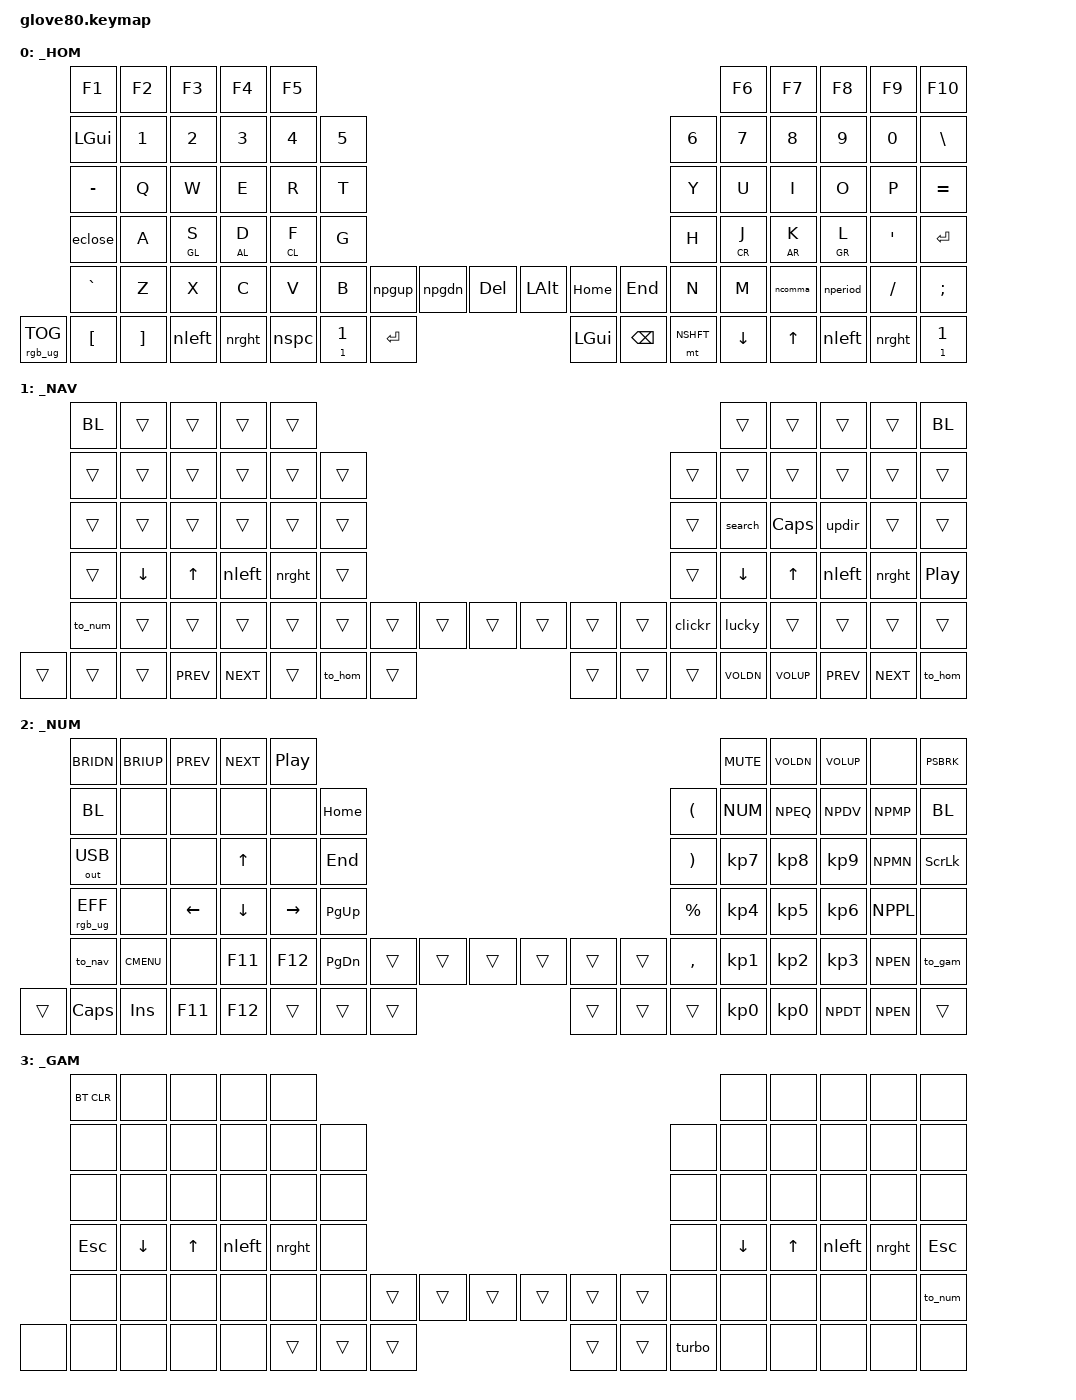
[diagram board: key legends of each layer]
#include <behaviors.dtsi>
#include <dt-bindings/zmk/keys.h>
#include <dt-bindings/zmk/bt.h>
#include <dt-bindings/zmk/ext_power.h>
#include <dt-bindings/zmk/outputs.h>
#include <dt-bindings/zmk/rgb.h>
// mouse import
#include <dt-bindings/zmk/mouse.h>

// helpers
#include "zmk-helpers/helper.h"
// Source desired key-position labels
#include "zmk-helpers/key-labels/glove80.h"

// layers
#define _HOM 0
#define _NAV 1
#define _NUM 2
#define _GAM 3

#define _________ &trans
#define XXXXXXXXX &none

// syntax shortening
#define BRIDN   C_BRI_DN
#define BRIUP   C_BRI_UP
#define PREV    C_PREV
#define NEXT    C_NEXT
#define MUTE    C_MUTE
#define VOLDN   C_VOL_DN
#define VOLUP   C_VOL_UP
#define PSBRK   PAUSE_BREAK
#define NUM     KP_NUM
#define NPEQ    KP_EQUAL
#define NPDV    KP_DIVIDE
#define NPMP    KP_MULTIPLY
#define NPMN    KP_MINUS
#define NPPL    KP_PLUS
#define NPEN    KP_ENTER
#define NPDT    KP_DOT
#define CMENU   K_CMENU
#define CLR     BT_CLR
#define BL bootloader

//left hand mod shortenings
#define CL      LCTRL
#define SL      LSHFT
#define AL      LALT
#define GL      LGUI

//right hand mod shortening
#define CR      RCTRL
#define SR      RSHFT
#define AR      RALT
#define GR      RGUI

// customs
#define NSHFT   RSHIFT TAB
#define NCTRL   LCTRL SP

#define BLU        170
#define GRN         85
#define RED          0
#define PNK        260

#define SAT        100  //saturation
#define BRT         50  //brightness

#define KEYS_L  LC5 LC4 LC3 LC2 LC1 LN5 LN4 LN3 LN2 LN1 LN0 LT5 LT4 LT3 LT2 LT1 LT0 LM5 LM4 LM3 LM2 LM1 LM0 LB5 LB4 LB3 LB2 LB1 LB0 LF5 LF4 LF3 LF2 LF1 // left-hand keys
#define KEYS_R  RC5 RC4 RC3 RC2 RC1 RN5 RN4 RN3 RN2 RN1 RN0 RT5 RT4 RT3 RT2 RT1 RT0 RM5 RM4 RM3 RM2 RM1 RM0 RB5 RB4 RB3 RB2 RB1 RB0 RF5 RF4 RF3 RF2 RF1 // rght-hand keys
#define THUMBS  LH5 LH4 LH3 RH3 RH4 RH5 LH2 LH1 LH0 RH0 RH1 RH2

/* left-hand HRMs */
ZMK_HOLD_TAP(hml,
    flavor = "balanced";
    tapping-term-ms = <280>;
    quick-tap-ms = <200>;                // repeat on tap-into-hold
    require-prior-idle-ms = <150>;
    bindings = <&kp>, <&kp>;
    hold-trigger-key-positions = <KEYS_R THUMBS>;
    hold-trigger-on-release;             // delay positional check until key-release
)
/* right-hand HRMs */
ZMK_HOLD_TAP(hmr,
    flavor = "balanced";
    tapping-term-ms = <280>;
    quick-tap-ms = <200>;                // repeat on tap-into-hold
    require-prior-idle-ms = <150>;
    bindings = <&kp>, <&kp>;
    hold-trigger-key-positions = <KEYS_L THUMBS>;
    hold-trigger-on-release;             // delay positional check until key-release
)


/ {
    macros {
        search: search_highlighted_selection {
            compatible = "zmk,behavior-macro";
            #binding-cells = <0>;
            wait-ms = <30>;
            tap-ms = <30>;
            bindings
                = <&macro_press &kp LCTRL>
                , <&macro_tap &kp C &kp T &kp V>
                , <&macro_release &kp LCTRL>
                , <&macro_tap &kp ENTER>
                ;
        };
        lucky: lucky_search_highlighted_selection {
            compatible = "zmk,behavior-macro";
            #binding-cells = <0>;
            wait-ms = <30>;
            tap-ms = <30>;
            bindings

                // CTRL(C T)
                = <&macro_press &hello_world>
                // , <&macro_tap &kp C &kp T>
                // , <&macro_release &kp LCTRL>

                // // HTTPS
                // , <&macro_tap &kp H &kp T &kp T &kp P &kp S>

                // // :
                // , <&macro_press &kp LSHFT>
                // , <&macro_tap &kp SEMI &kp SEMI>
                // , <&macro_release &kp LSHFT>

                // // //www.google.com/search
                // , <&macro_tap &kp FSLH &kp FSLH &kp W &kp W &kp W &kp DOT &kp G &kp O &kp O &kp G &kp L &kp E &kp DOT &kp C &kp O &kp M &kp FSLH &kp S &kp E &kp A &kp R &kp C>

                // , <&macro_tap &kp H>


                // // ?
                // , <&macro_press &kp LSHFT>
                // , <&macro_tap &kp SEMI>
                // , <&macro_release &kp LSHFT>

                // // copy paste
                // , <&macro_press &kp LCTRL>
                // , <&macro_tap &kp V>
                // , <&macro_release &kp LCTRL>

                // // &
                // , <&macro_press &kp LSHFT>
                // , <&macro_tap &kp N7>
                // , <&macro_release &kp LSHFT>

                // // btnI=I
                // , <&macro_tap &kp B &kp T &kp N &kp I &kp EQUAL &kp I>
                // , <&macro_tap &kp ENTER>
                // // "https://www.google.com/search?q=" SS_LCTL("v") "&btnI=I"
                ;
        };
        cntrc: click_center {
            compatible = "zmk,behavior-macro";
            #binding-cells = <0>;
            bindings
                = <&macro_wait_time 50>
                , <&macro_tap &kp F20 &mkp LCLK>
                ;
        };
        sidec: click_side {
            compatible = "zmk,behavior-macro";
            #binding-cells = <0>;
            bindings
                = <&macro_wait_time 50>
                , <&macro_tap &kp F19 &mkp LCLK>
                ;
        };
        updir: up_directory {
            compatible = "zmk,behavior-macro";
            #binding-cells = <0>;
            wait-ms = <1>;
            tap-ms = <1>;
            bindings
                = <&macro_wait_time 1>
                , <&macro_tap &kp DOT &kp DOT &kp FSLH>
                ;
        };
        to_hom: to_hom {
            compatible = "zmk,behavior-macro";
            wait-ms = <0>;
            tap-ms = <0>;
            #binding-cells = <0>;
            bindings
                = <&macro_press &to _HOM>
                , <&macro_tap &rgb_ug RGB_COLOR_HSB(BLU, SAT, BRT)>
                ;
        };
        to_nav: to_nav {
            compatible = "zmk,behavior-macro";
            wait-ms = <0>;
            tap-ms = <0>;
            #binding-cells = <0>;
            bindings
                = <&macro_press &to _NAV>
                , <&macro_tap &rgb_ug RGB_COLOR_HSB(RED, SAT, BRT)>
                ;
        };
        to_num: to_num {
            compatible = "zmk,behavior-macro";
            wait-ms = <0>;
            tap-ms = <0>;
            #binding-cells = <0>;
            bindings
                = <&macro_press &to _NUM>
                , <&macro_tap &rgb_ug RGB_COLOR_HSB(GRN, SAT, BRT)>
                ;
        };
        to_gam: to_gam {
            compatible = "zmk,behavior-macro";
            wait-ms = <0>;
            tap-ms = <0>;
            #binding-cells = <0>;
            bindings
                = <&macro_press &to _GAM>
                , <&macro_tap &rgb_ug RGB_COLOR_HSB(PNK, SAT, BRT)>
                ;
        };
        htonmo: home_to_nav_momentary {
            compatible = "zmk,behavior-macro";
            wait-ms = <0>;
            tap-ms = <0>;
            #binding-cells = <0>;
            bindings
                = <&macro_tap &rgb_ug RGB_COLOR_HSB(RED, SAT, BRT)>
                , <&macro_press &mo _NAV>
                , <&macro_pause_for_release>
                , <&macro_release &mo _NAV>
                , <&macro_tap &rgb_ug RGB_COLOR_HSB(BLU, SAT, BRT)>
                ;
        };
        turbo: turbo_mouse_click {
            compatible = "zmk,behavior-macro";
            // wait-ms = <5>;
            // tap-ms = <5>;
            #binding-cells = <0>;
            bindings
                = <&macro_tap &mkp LCLK &mkp LCLK &mkp LCLK &mkp LCLK>
                ;
        };
    };

    behaviors {
        hello_world: hello_world {
            compatible = "zmk,behavior-send-string";
            #binding-cells = <0>;
            text = "Hello, world!";
        };

        mtly: mod_tap_layer {
            compatible = "zmk,behavior-hold-tap";
            #binding-cells = <2>;
            tapping-term-ms = <200>;
            bindings = <&htonmo>, <&to_nav>;
        };

        //  SHIFT
        //-----------------------------------------------------------------------------------------------------------------------------------
        npgup: npgdn_up {                                   // Shift + PGUP  = SHFT + WIN + Left        (Send Desktop Left)
            compatible = "zmk,behavior-mod-morph";
            #binding-cells = <0>;
            bindings = <&kp PG_UP>, <&kp LS(LG(LEFT))>;
            mods = <(MOD_LSFT|MOD_RSFT)>;
        };
        npgdn: new_page_down {                              // Shift + PGDN  = SHFT + WIN + Right       (Send Desktop Right)
            compatible = "zmk,behavior-mod-morph";
            #binding-cells = <0>;
            bindings = <&kp PG_DN>, <&kp LS(LG(RIGHT))>;
            mods = <(MOD_LSFT|MOD_RSFT)>;
        };
        intleft: left_intermediate {                        // Shift + Left  = WIN  + CTRL + Left       (Move Desktop Left)
            compatible = "zmk,behavior-mod-morph";
            #binding-cells = <0>;
            bindings = <&kp LEFT>, <&kp LC(LG(LEFT))>;
            mods = <(MOD_LSFT|MOD_RSFT)>;
        };
        intright: right_intermediate {                      // Shift + Right = WIN  + CTRL + Rght       (Move Desktop Right)
            compatible = "zmk,behavior-mod-morph";
            #binding-cells = <0>;
            bindings = <&kp RIGHT>, <&kp LC(LG(RIGHT))>;
            mods = <(MOD_LSFT|MOD_RSFT)>;
        };
        nspc: new_space {                                   // Shift + Space = ALT + LEFT               (Previous)
            compatible = "zmk,behavior-mod-morph";
            #binding-cells = <0>;
            bindings = <&kp SPC>, <&kp LA(LEFT)>;
            mods = <(MOD_LSFT|MOD_RSFT)>;
        };
        clickr: clicker {                                   // Shift + clickr= click left
            compatible = "zmk,behavior-mod-morph";
            #binding-cells = <0>;
            bindings = <&cntrc>, <&sidec>;
            mods = <(MOD_LSFT|MOD_RSFT)>;
        };

        //  CONTROL
        //-----------------------------------------------------------------------------------------------------------------------------------
        eclose: escape_close {                              // Ctrl  + ESC   = ALT + F4                 (Close Window)
            compatible = "zmk,behavior-mod-morph";
            #binding-cells = <0>;
            bindings = <&kp ESC>, <&kp LA(F4)>;
            mods = <(MOD_LCTL|MOD_RCTL)>;
        };
        nleft: new_left_arrow {                             // Ctrl  + Left  = SHFT + CTRL + TAB        (Move Left One Tab)
            compatible = "zmk,behavior-mod-morph";
            #binding-cells = <0>;
            bindings = <&intleft>, <&kp LC(LS(TAB))>;
            mods = <(MOD_LCTL|MOD_RCTL)>;
        };
        nrght: new_right_arrow {                            // Ctrl  + Right = CTRL + TAB               (Move Right One Tab)
            compatible = "zmk,behavior-mod-morph";
            #binding-cells = <0>;
            bindings = <&intright>, <&kp LC(TAB)>;
            mods = <(MOD_LCTL|MOD_RCTL)>;
        };
        ncomma: new_comma {                                 // Ctrl  +  ,    =  (
            compatible = "zmk,behavior-mod-morph";
            #binding-cells = <0>;
            bindings = <&kp COMMA>, <&kp LS(N9)>;
            mods = <(MOD_LCTL|MOD_RCTL)>;
        };
        nperiod: new_period {                               // Ctrl  +  .    =  )
            compatible = "zmk,behavior-mod-morph";
            #binding-cells = <0>;
            bindings = <&kp DOT>, <&kp LS(N0)>;
            mods = <(MOD_LCTL|MOD_RCTL)>;
        };
    };


    keymap {
        compatible = "zmk,keymap";

        _HOM {
            bindings = <
            // ┌─────────┬─────────┬─────────┬─────────┬─────────┐                                                                                 ┌─────────┬─────────┬─────────┬─────────┬─────────┐
            // |    F1   |    F2   |    F3   |    F4   |    F5   |                                                                                 |    F6   |    F7   |    F8   |    F9   |    F10  |
                &kp F1    &kp F2    &kp F3    &kp F4    &kp F5                                                                                      &kp F6    &kp F7    &kp F8    &kp F9    &kp F10
            // ├─────────┼─────────┼─────────┼─────────┼─────────┼─────────┐                                                             ┌─────────┼─────────┼─────────┼─────────┼─────────┼─────────┤
            // |   GUI   |    1    |    2    |    3    |    4    |    5    |                                                             |    6    |    7    |    8    |    9    |    0    |    \    |
                &kp LGUI  &kp N1    &kp N2    &kp N3    &kp N4    &kp N5                                                                  &kp N6    &kp N7    &kp N8    &kp N9    &kp N0    &kp BSLH
            // ├─────────┼─────────┼─────────┼─────────┼─────────┼─────────┤                                                             ├─────────┼─────────┼─────────┼─────────┼─────────┼─────────┤
            // |    -    |    Q    |    W    |    E    |    R    |    T    |                                                             |    Y    |    U    |    I    |    O    |    P    |    =    |
                &kp MINUS &kp Q     &kp W     &kp E     &kp R     &kp T                                                                   &kp Y     &kp U     &kp I     &kp O     &kp P     &kp EQUAL
            // ├─────────┼─────────┼─────────┼─────────┼─────────┼─────────┤                                                             ├─────────┼─────────┼─────────┼─────────┼─────────┼─────────┤
            // |   ESC   |    A    |    S    |    D    |    F    |    G    |                                                             |    H    |    J    |    K    |    L    |    '    |  ENTER  |
                &eclose   &kp A     &hml GL S &hml AL D &hml CL F &kp G                                                                   &kp H     &hmr CR J &hmr AR K &hmr GR L &kp SQT   &kp ENTER
            // ├─────────┼─────────┼─────────┼─────────┼─────────┼─────────┼─────────┬─────────┬─────────┐ ┌─────────┬─────────┬─────────┼─────────┼─────────┼─────────┼─────────┼─────────┼─────────┤
            // |    `    |    Z    |    X    |    C    |    V    |    B    |  PGUP   |  PGDN   | DELETE  | |   ALT   |  HOME   |   END   |    N    |    M    |    ,    |    .    |    /    |    ;    |
                &kp GRAVE &kp Z     &kp X     &kp C     &kp V     &kp B     &npgup    &npgdn    &kp DEL     &kp LALT  &kp HOME  &kp END   &kp N     &kp M     &ncomma   &nperiod  &kp FSLH  &kp SEMI
            // ├─────────┼─────────┼─────────┼─────────┼─────────┼─────────┼─────────┼─────────┼─────────┤ ├─────────┼─────────┼─────────┼─────────┼─────────┼─────────┼─────────┼─────────┼─────────┤
            // |  MAGIC  |    [    |    ]    |  LEFT   |  RIGHT  |         | Control |  LAYER  |  ENTER  | |   GUI   |BACKSPACE|  SHIFT  |         |   UP    |  DOWN   |  LEFT   |  RIGHT  |  PGDN   |
          &rgb_ug RGB_TOG &kp LBKT  &kp RBKT  &nleft    &nrght              &nspc     &mtly 1 1 &kp ENTER   &kp LGUI  &kp BSPC  &mt NSHFT           &kp DOWN  &kp UP    &nleft    &nrght    &mtly 1 1
            // └─────────┴─────────┴─────────┴─────────┴─────────┘         └─────────┴─────────┴─────────┘ └─────────┴─────────┴─────────┘         └─────────┴─────────┴─────────┴─────────┴─────────┘
            >;
        };

        _NAV {
            bindings = <
            // ┌─────────┬─────────┬─────────┬─────────┬─────────┐                                                                                 ┌─────────┬─────────┬─────────┬─────────┬─────────┐
            // |    F1   |    F2   |    F3   |    F4   |    F5   |                                                                                 |    F6   |    F7   |    F8   |    F9   |    F10  |
                &BL       _________ _________ _________ _________                                                                                   _________ _________ _________ _________ &BL
            // ├─────────┼─────────┼─────────┼─────────┼─────────┼─────────┐                                                             ┌─────────┼─────────┼─────────┼─────────┼─────────┼─────────┤
            // |   GUI   |    1    |    2    |    3    |    4    |    5    |                                                             |    6    |    7    |    8    |    9    |    0    |    \    |
                _________ _________ _________ _________ _________ _________                                                               _________ _________ _________ _________ _________ _________
            // ├─────────┼─────────┼─────────┼─────────┼─────────┼─────────┤                                                             ├─────────┼─────────┼─────────┼─────────┼─────────┼─────────┤
            // |    -    |    Q    |    W    |    E    |    R    |    T    |                                                             |    Y    |    U    |    I    |    O    |    P    |    =    |
                _________ _________ _________ _________ _________ _________                                                               _________ &search   &kp CAPS  &updir    _________ _________
            // ├─────────┼─────────┼─────────┼─────────┼─────────┼─────────┤                                                             ├─────────┼─────────┼─────────┼─────────┼─────────┼─────────┤
            // |   ESC   |    A    |    S    |    D    |    F    |    G    |                                                             |    H    |    J    |    K    |    L    |    '    |  ENTER  |
                _________ &kp DOWN  &kp UP    &nleft    &nrght    _________                                                               _________ &kp DOWN  &kp UP    &nleft    &nrght    &kp C_PP
            // ├─────────┼─────────┼─────────┼─────────┼─────────┼─────────┼─────────┬─────────┬─────────┐ ┌─────────┬─────────┬─────────┼─────────┼─────────┼─────────┼─────────┼─────────┼─────────┤
            // |    `    |    Z    |    X    |    C    |    V    |    B    |  PGUP   |  PGDN   | DELETE  | |   ALT   |  HOME   |   END   |    N    |    M    |    ,    |    .    |    /    |    ;    |
                &to_num   _________ _________ _________ _________ _________ _________ _________ _________   _________ _________ _________ &clickr   &lucky    _________ _________ _________ _________
            // ├─────────┼─────────┼─────────┼─────────┼─────────┼─────────┼─────────┼─────────┼─────────┤ ├─────────┼─────────┼─────────┼─────────┼─────────┼─────────┼─────────┼─────────┼─────────┤
            // |  MAGIC  |    [    |    ]    |  LEFT   |  RIGHT  |         | Control |  LAYER  |  ENTER  | |   GUI   |BACKSPACE|  SHIFT  |         |   UP    |  DOWN   |  LEFT   |  RIGHT  |  PGDN   |
                _________ _________ _________ &kp PREV  &kp NEXT            _________ &to_hom   _________   _________ _________ _________           &kp VOLDN &kp VOLUP &kp PREV  &kp NEXT  &to_hom
            // └─────────┴─────────┴─────────┴─────────┴─────────┘         └─────────┴─────────┴─────────┘ └─────────┴─────────┴─────────┘         └─────────┴─────────┴─────────┴─────────┴─────────┘
            >;
        };

        _NUM {
            bindings = <
            // ┌─────────┬─────────┬─────────┬─────────┬─────────┐                                                                                 ┌─────────┬─────────┬─────────┬─────────┬─────────┐
            // |    F1   |    F2   |    F3   |    F4   |    F5   |                                                                                 |    F6   |    F7   |    F8   |    F9   |    F10  |
                &kp BRIDN &kp BRIUP &kp PREV  &kp NEXT  &kp C_PP                                                                                    &kp MUTE  &kp VOLDN &kp VOLUP XXXXXXXXX &kp PSBRK
            // ├─────────┼─────────┼─────────┼─────────┼─────────┼─────────┐                                                             ┌─────────┼─────────┼─────────┼─────────┼─────────┼─────────┤
            // |   GUI   |    1    |    2    |    3    |    4    |    5    |                                                             |    6    |    7    |    8    |    9    |    0    |    \    |
                &BL       XXXXXXXXX XXXXXXXXX XXXXXXXXX XXXXXXXXX &kp HOME                                                                &kp LPAR  &kp NUM   &kp NPEQ  &kp NPDV  &kp NPMP  &BL
            // ├─────────┼─────────┼─────────┼─────────┼─────────┼─────────┤                                                             ├─────────┼─────────┼─────────┼─────────┼─────────┼─────────┤
            // |    -    |    Q    |    W    |    E    |    R    |    T    |                                                             |    Y    |    U    |    I    |    O    |    P    |    =    |
                &out OUT_USB &none  XXXXXXXXX &kp UP    XXXXXXXXX &kp END                                                                 &kp RPAR  &kp KP_N7 &kp KP_N8 &kp KP_N9 &kp NPMN  &kp SLCK
            // ├─────────┼─────────┼─────────┼─────────┼─────────┼─────────┤                                                             ├─────────┼─────────┼─────────┼─────────┼─────────┼─────────┤
            // |   ESC   |    A    |    S    |    D    |    F    |    G    |                                                             |    H    |    J    |    K    |    L    |    '    |  ENTER  |
          &rgb_ug RGB_EFF XXXXXXXXX &kp LEFT  &kp DOWN  &kp RIGHT &kp PG_UP                                                               &kp PRCNT &kp KP_N4 &kp KP_N5 &kp KP_N6 &kp NPPL  XXXXXXXXX
            // ├─────────┼─────────┼─────────┼─────────┼─────────┼─────────┼─────────┬─────────┬─────────┐ ┌─────────┬─────────┬─────────┼─────────┼─────────┼─────────┼─────────┼─────────┼─────────┤
            // |    `    |    Z    |    X    |    C    |    V    |    B    |  PGUP   |  PGDN   | DELETE  | |   ALT   |  HOME   |   END   |    N    |    M    |    ,    |    .    |    /    |    ;    |
                &to_nav   &kp CMENU XXXXXXXXX &kp F11   &kp F12   &kp PG_DN _________ _________ _________   _________ _________ _________ &kp COMMA &kp KP_N1 &kp KP_N2 &kp KP_N3 &kp NPEN  &to_gam
            // ├─────────┼─────────┼─────────┼─────────┼─────────┼─────────┼─────────┼─────────┼─────────┤ ├─────────┼─────────┼─────────┼─────────┼─────────┼─────────┼─────────┼─────────┼─────────┤
            // |  MAGIC  |    [    |    ]    |  LEFT   |  RIGHT  |         | Control |  LAYER  |  ENTER  | |   GUI   |BACKSPACE|  SHIFT  |         |   UP    |  DOWN   |  LEFT   |  RIGHT  |  PGDN   |
                _________ &kp CAPS  &kp INS   &kp F11   &kp F12             _________ _________ _________   _________ _________ _________           &kp KP_N0 &kp KP_N0 &kp NPDT  &kp NPEN  _________
            // └─────────┴─────────┴─────────┴─────────┴─────────┘         └─────────┴─────────┴─────────┘ └─────────┴─────────┴─────────┘         └─────────┴─────────┴─────────┴─────────┴─────────┘
            >;
        };

        _GAM {
            bindings = <
            // ┌─────────┬─────────┬─────────┬─────────┬─────────┐                                                                                 ┌─────────┬─────────┬─────────┬─────────┬─────────┐
            // |    F1   |    F2   |    F3   |    F4   |    F5   |                                                                                 |    F6   |    F7   |    F8   |    F9   |    F10  |
                &bt CLR   XXXXXXXXX XXXXXXXXX XXXXXXXXX XXXXXXXXX                                                                                   XXXXXXXXX XXXXXXXXX XXXXXXXXX XXXXXXXXX XXXXXXXXX
            // ├─────────┼─────────┼─────────┼─────────┼─────────┼─────────┐                                                             ┌─────────┼─────────┼─────────┼─────────┼─────────┼─────────┤
            // |   GUI   |    1    |    2    |    3    |    4    |    5    |                                                             |    6    |    7    |    8    |    9    |    0    |    \    |
                XXXXXXXXX XXXXXXXXX XXXXXXXXX XXXXXXXXX XXXXXXXXX XXXXXXXXX                                                               XXXXXXXXX XXXXXXXXX XXXXXXXXX XXXXXXXXX XXXXXXXXX XXXXXXXXX
            // ├─────────┼─────────┼─────────┼─────────┼─────────┼─────────┤                                                             ├─────────┼─────────┼─────────┼─────────┼─────────┼─────────┤
            // |    -    |    Q    |    W    |    E    |    R    |    T    |                                                             |    Y    |    U    |    I    |    O    |    P    |    =    |
                XXXXXXXXX XXXXXXXXX XXXXXXXXX XXXXXXXXX XXXXXXXXX XXXXXXXXX                                                               XXXXXXXXX XXXXXXXXX XXXXXXXXX XXXXXXXXX XXXXXXXXX XXXXXXXXX
            // ├─────────┼─────────┼─────────┼─────────┼─────────┼─────────┤                                                             ├─────────┼─────────┼─────────┼─────────┼─────────┼─────────┤
            // |   ESC   |    A    |    S    |    D    |    F    |    G    |                                                             |    H    |    J    |    K    |    L    |    '    |  ENTER  |
                &kp ESC   &kp DOWN  &kp UP    &nleft    &nrght    XXXXXXXXX                                                               XXXXXXXXX &kp DOWN  &kp UP    &nleft    &nrght    &kp ESC
            // ├─────────┼─────────┼─────────┼─────────┼─────────┼─────────┼─────────┬─────────┬─────────┐ ┌─────────┬─────────┬─────────┼─────────┼─────────┼─────────┼─────────┼─────────┼─────────┤
            // |    `    |    Z    |    X    |    C    |    V    |    B    |  PGUP   |  PGDN   | DELETE  | |   ALT   |  HOME   |   END   |    N    |    M    |    ,    |    .    |    /    |    ;    |
                XXXXXXXXX XXXXXXXXX XXXXXXXXX XXXXXXXXX XXXXXXXXX XXXXXXXXX _________ _________ _________   _________ _________ _________ XXXXXXXXX XXXXXXXXX XXXXXXXXX XXXXXXXXX XXXXXXXXX &to_num
            // ├─────────┼─────────┼─────────┼─────────┼─────────┼─────────┼─────────┼─────────┼─────────┤ ├─────────┼─────────┼─────────┼─────────┼─────────┼─────────┼─────────┼─────────┼─────────┤
            // |  MAGIC  |    [    |    ]    |  LEFT   |  RIGHT  |         | Control |  LAYER  |  ENTER  | |   GUI   |BACKSPACE|  SHIFT  |         |   UP    |  DOWN   |  LEFT   |  RIGHT  |  PGDN   |
                XXXXXXXXX XXXXXXXXX XXXXXXXXX XXXXXXXXX XXXXXXXXX           _________ _________ _________   _________ _________ &turbo              XXXXXXXXX XXXXXXXXX XXXXXXXXX XXXXXXXXX XXXXXXXXX
            // └─────────┴─────────┴─────────┴─────────┴─────────┘         └─────────┴─────────┴─────────┘ └─────────┴─────────┴─────────┘         └─────────┴─────────┴─────────┴─────────┴─────────┘
            >;
        };

// ----------------------------------------------------------------------------------------------------------------------------------------------------------------------------------------------------------
    };
};
